# EFM32PG1B100F128GM32 register map
File version: 4.2.0
Registers are 32-bit, read-write, reset 0x0 unless marked. A register's access mark holds for its fields unless they carry their own. Offsets are from the block's base; [hi:lo] are bit positions; 'fields as' and 'values as' point back to an identical list.

## EMU
Base 0x400E3000
0x00 CTRL — Control Register
  [1] EM2BLOCK — Energy Mode 2 Block
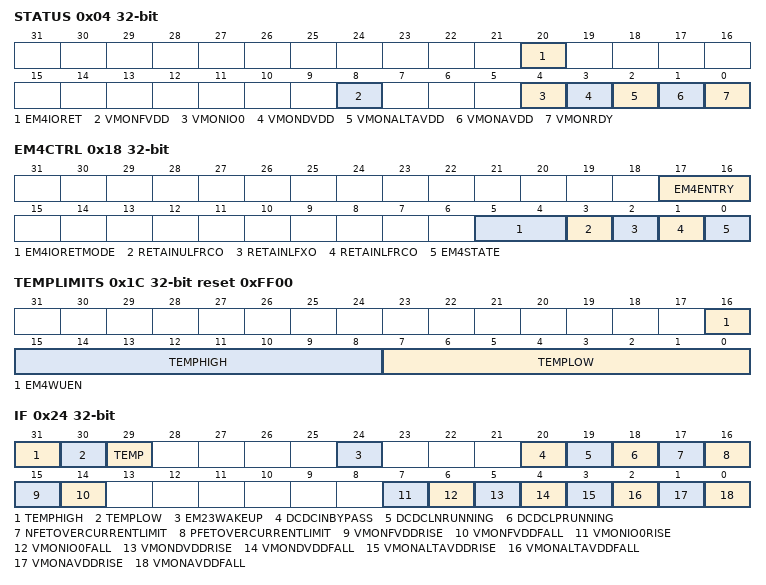
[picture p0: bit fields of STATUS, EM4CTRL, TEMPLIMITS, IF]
0x04 STATUS ro
  [20] EM4IORET — IO Retention Status
  [8] VMONFVDD — VMON VDDFLASH Channel.
  [4] VMONIO0 — VMON IOVDD0 Channel.
  [3] VMONDVDD — VMON DVDD Channel.
  [2] VMONALTAVDD — Alternate VMON AVDD Channel.
  [1] VMONAVDD — VMON AVDD Channel.
  [0] VMONRDY — VMON ready
0x08 LOCK — Configuration Lock Register
  [15:0] LOCKKEY — Configuration Lock Key
    0=UNLOCKED; 1=LOCKED
0x0C RAM0CTRL — Memory Control Register
  [3:0] RAMPOWERDOWN — RAM0 blockset power-down
    0=NONE (None of the RAM blocks powered down); 8=BLK4 (Power down RAM blocks 4 and above (address range 0x20006000-0x20007BFF)); 12=BLK3TO4 (Power down RAM blocks 3 and above (address range 0x20004000-0x20007BFF)); 14=BLK2TO4 (Power down RAM blocks 2 and above (address range 0x20002000-0x20007BFF)); 15=BLK1TO4 (Power down RAM blocks 1 and above (address range 0x20001000-0x20007BFF))
0x10 CMD wo — Command Register
  [0] EM4UNLATCH
0x14 PERACTCONF — Peripheral to Peripheral Activation Clock Configuration
  [0] RACPER — Enable PER clock when RAC is activated
0x18 EM4CTRL — EM4 Control Register
  [17:16] EM4ENTRY wo — Energy Mode 4 Entry
  [5:4] EM4IORETMODE — EM4 IO Retention Disable
    0=DISABLE (No Retention: Pads enter reset state when entering EM4); 1=EM4EXIT (Retention through EM4: Pads enter reset state when exiting EM4); 2=SWUNLATCH (Retention through EM4 and Wakeup: software writes UNLATCH register to remove retention)
  [3] RETAINULFRCO — ULFRCO Retain during EM4S
  [2] RETAINLFXO — LFXO Retain during EM4
  [1] RETAINLFRCO — LFRCO Retain during EM4
  [0] EM4STATE — Energy Mode 4 State
0x1C TEMPLIMITS reset 0xFF00 — Temperature limits for interrupt generation
  [16] EM4WUEN — Enable EM4 Wakeup due to low/high temerature
  [15:8] TEMPHIGH — Temperature High Limit
  [7:0] TEMPLOW — Temperature Low Limit
0x20 TEMP ro — Value of last temperature measurement
  [7:0] TEMP — Temperature Measurement
0x24 IF ro — Interrupt Flag Register
  [31] TEMPHIGH — Temperature High Limit Reached
  [30] TEMPLOW — Temperature Low Limit Reached
  [29] TEMP — New Temperature Measurement Valid
  [24] EM23WAKEUP — Wakeup IRQ from EM2 and EM3
  [20] DCDCINBYPASS — DCDC is in bypass
  [19] DCDCLNRUNNING — LN mode is running
  [18] DCDCLPRUNNING — LP mode is running
  [17] NFETOVERCURRENTLIMIT — NFET current limit hit
  [16] PFETOVERCURRENTLIMIT — PFET current limit hit
  [15] VMONFVDDRISE — VMON VDDFLASH Channel Rise
  [14] VMONFVDDFALL — VMON VDDFLASH Channel Fall
  [7] VMONIO0RISE — VMON IOVDD0 Channel Rise
  [6] VMONIO0FALL — VMON IOVDD0 Channel Fall
  [5] VMONDVDDRISE — VMON DVDD Channel Rise
  [4] VMONDVDDFALL — VMON DVDD Channel Fall
  [3] VMONALTAVDDRISE — Alternate VMON AVDD Channel Rise
  [2] VMONALTAVDDFALL — Alternate VMON AVDD Channel Fall
  [1] VMONAVDDRISE — VMON AVDD Channel Rise
  [0] VMONAVDDFALL — VMON AVDD Channel Fall
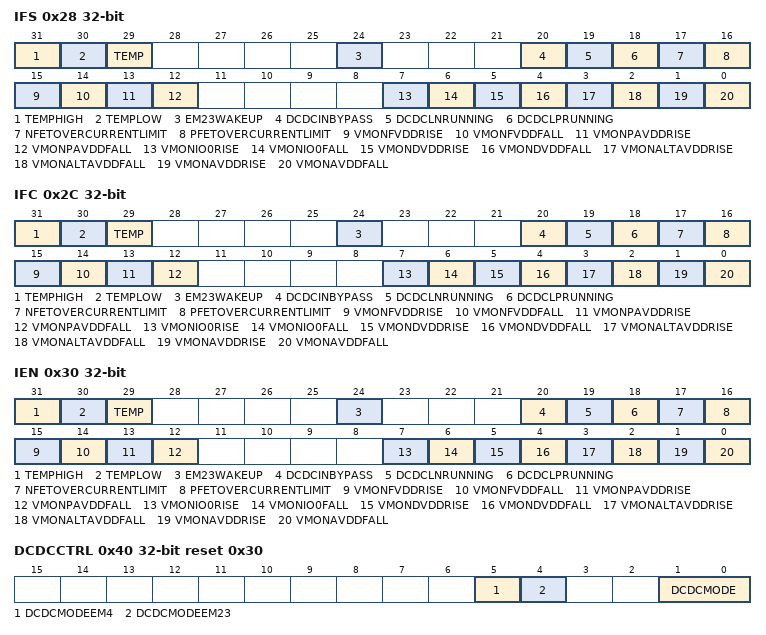
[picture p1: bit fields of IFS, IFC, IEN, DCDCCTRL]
0x28 IFS wo — Interrupt Flag Set Register
  [31] TEMPHIGH — Set TEMPHIGH Interrupt Flag
  [30] TEMPLOW — Set TEMPLOW Interrupt Flag
  [29] TEMP — Set TEMP Interrupt Flag
  [24] EM23WAKEUP — Set EM23WAKEUP Interrupt Flag
  [20] DCDCINBYPASS — Set DCDCINBYPASS Interrupt Flag
  [19] DCDCLNRUNNING — Set DCDCLNRUNNING Interrupt Flag
  [18] DCDCLPRUNNING — Set DCDCLPRUNNING Interrupt Flag
  [17] NFETOVERCURRENTLIMIT — Set NFETOVERCURRENTLIMIT Interrupt Flag
  [16] PFETOVERCURRENTLIMIT — Set PFETOVERCURRENTLIMIT Interrupt Flag
  [15] VMONFVDDRISE — Set VMONFVDDRISE Interrupt Flag
  [14] VMONFVDDFALL — Set VMONFVDDFALL Interrupt Flag
  [13] VMONPAVDDRISE — Set VMONPAVDDRISE Interrupt Flag
  [12] VMONPAVDDFALL — Set VMONPAVDDFALL Interrupt Flag
  [7] VMONIO0RISE — Set VMONIO0RISE Interrupt Flag
  [6] VMONIO0FALL — Set VMONIO0FALL Interrupt Flag
  [5] VMONDVDDRISE — Set VMONDVDDRISE Interrupt Flag
  [4] VMONDVDDFALL — Set VMONDVDDFALL Interrupt Flag
  [3] VMONALTAVDDRISE — Set VMONALTAVDDRISE Interrupt Flag
  [2] VMONALTAVDDFALL — Set VMONALTAVDDFALL Interrupt Flag
  [1] VMONAVDDRISE — Set VMONAVDDRISE Interrupt Flag
  [0] VMONAVDDFALL — Set VMONAVDDFALL Interrupt Flag
0x2C IFC wo — Interrupt Flag Clear Register
  [31] TEMPHIGH — Clear TEMPHIGH Interrupt Flag
  [30] TEMPLOW — Clear TEMPLOW Interrupt Flag
  [29] TEMP — Clear TEMP Interrupt Flag
  [24] EM23WAKEUP — Clear EM23WAKEUP Interrupt Flag
  [20] DCDCINBYPASS — Clear DCDCINBYPASS Interrupt Flag
  [19] DCDCLNRUNNING — Clear DCDCLNRUNNING Interrupt Flag
  [18] DCDCLPRUNNING — Clear DCDCLPRUNNING Interrupt Flag
  [17] NFETOVERCURRENTLIMIT — Clear NFETOVERCURRENTLIMIT Interrupt Flag
  [16] PFETOVERCURRENTLIMIT — Clear PFETOVERCURRENTLIMIT Interrupt Flag
  [15] VMONFVDDRISE — Clear VMONFVDDRISE Interrupt Flag
  [14] VMONFVDDFALL — Clear VMONFVDDFALL Interrupt Flag
  [13] VMONPAVDDRISE — Clear VMONPAVDDRISE Interrupt Flag
  [12] VMONPAVDDFALL — Clear VMONPAVDDFALL Interrupt Flag
  [7] VMONIO0RISE — Clear VMONIO0RISE Interrupt Flag
  [6] VMONIO0FALL — Clear VMONIO0FALL Interrupt Flag
  [5] VMONDVDDRISE — Clear VMONDVDDRISE Interrupt Flag
  [4] VMONDVDDFALL — Clear VMONDVDDFALL Interrupt Flag
  [3] VMONALTAVDDRISE — Clear VMONALTAVDDRISE Interrupt Flag
  [2] VMONALTAVDDFALL — Clear VMONALTAVDDFALL Interrupt Flag
  [1] VMONAVDDRISE — Clear VMONAVDDRISE Interrupt Flag
  [0] VMONAVDDFALL — Clear VMONAVDDFALL Interrupt Flag
0x30 IEN — Interrupt Enable Register
  [31] TEMPHIGH — TEMPHIGH Interrupt Enable
  [30] TEMPLOW — TEMPLOW Interrupt Enable
  [29] TEMP — TEMP Interrupt Enable
  [24] EM23WAKEUP — EM23WAKEUP Interrupt Enable
  [20] DCDCINBYPASS — DCDCINBYPASS Interrupt Enable
  [19] DCDCLNRUNNING — DCDCLNRUNNING Interrupt Enable
  [18] DCDCLPRUNNING — DCDCLPRUNNING Interrupt Enable
  [17] NFETOVERCURRENTLIMIT — NFETOVERCURRENTLIMIT Interrupt Enable
  [16] PFETOVERCURRENTLIMIT — PFETOVERCURRENTLIMIT Interrupt Enable
  [15] VMONFVDDRISE — VMONFVDDRISE Interrupt Enable
  [14] VMONFVDDFALL — VMONFVDDFALL Interrupt Enable
  [13] VMONPAVDDRISE — VMONPAVDDRISE Interrupt Enable
  [12] VMONPAVDDFALL — VMONPAVDDFALL Interrupt Enable
  [7] VMONIO0RISE — VMONIO0RISE Interrupt Enable
  [6] VMONIO0FALL — VMONIO0FALL Interrupt Enable
  [5] VMONDVDDRISE — VMONDVDDRISE Interrupt Enable
  [4] VMONDVDDFALL — VMONDVDDFALL Interrupt Enable
  [3] VMONALTAVDDRISE — VMONALTAVDDRISE Interrupt Enable
  [2] VMONALTAVDDFALL — VMONALTAVDDFALL Interrupt Enable
  [1] VMONAVDDRISE — VMONAVDDRISE Interrupt Enable
  [0] VMONAVDDFALL — VMONAVDDFALL Interrupt Enable
0x34 PWRLOCK — Regulator and Supply Lock Register
  [15:0] LOCKKEY — Regulator and Supply Configuration Lock Key
    0=UNLOCKED; 1=LOCKED
0x38 PWRCFG — Power Configuration Register.
  [3:0] PWRCFG — Power Configuration
    0=STARTUP (Power up configuration. Works with any external configuration.); 1=NODCDC (DCDC Disabled. AVDD Bypassed to DVDD internally); 2=DCDCTODVDD (DCDC filterred and routed to DVDD)
0x3C PWRCTRL — Power Control Register.
  [5] ANASW — Analog Switch Selection
0x40 DCDCCTRL reset 0x30 — DCDC Control
  [5] DCDCMODEEM4 — Reserved for internal use. Do not change.
  [4] DCDCMODEEM23 — Reserved for internal use. Do not change.
  [1:0] DCDCMODE — Regulator Mode
    0=BYPASS (DCDC regulator is operating in bypass mode.); 1=LOWNOISE (DCDC regulator is operating in low noise mode.); 2=LOWPOWER (DCDC regulator is operating in low power mode.); 3=OFF (DCDC regulator is off. Note: DVDD must be supplied externally)
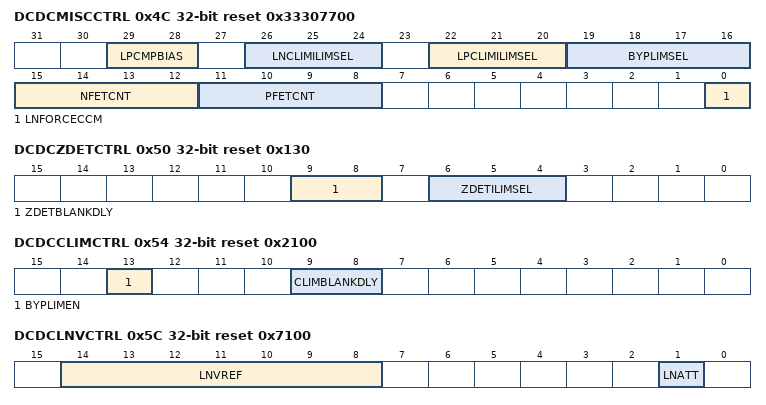
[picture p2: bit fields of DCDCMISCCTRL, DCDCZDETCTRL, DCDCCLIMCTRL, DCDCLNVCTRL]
0x4C DCDCMISCCTRL reset 0x33307700 — DCDC Miscellaneous Control Register
  [29:28] LPCMPBIAS — LP mode comparator bias selection
    0=BIAS0 (Nominal load current less than 10uA.); 1=BIAS1 (Nominal load current less than 100uA.); 2=BIAS2 (Nominal load current less than 1mA.); 3=BIAS3 (Nominal load current less than 10mA.)
  [26:24] LNCLIMILIMSEL — Current limiter current threshold selection during low noise mode
  [22:20] LPCLIMILIMSEL — Current limiter current threshold selection during low power mode
  [19:16] BYPLIMSEL — Current Limit In Bypass Mode
  [15:12] NFETCNT — NFET switch number selection
  [11:8] PFETCNT — PFET switch number selection
  [0] LNFORCECCM — Force DCDC into CCM mode in low noise operation
0x50 DCDCZDETCTRL reset 0x130 — DCDC Power Train NFET Zero Current Detector Control Register
  [9:8] ZDETBLANKDLY — Reserved for internal use. Do not change.
  [6:4] ZDETILIMSEL — Reverse current limit level for zero detector
0x54 DCDCCLIMCTRL reset 0x2100 — DCDC Power Train PFET Current Limiter Control Register
  [13] BYPLIMEN — Bypass Current Limit Enable
  [9:8] CLIMBLANKDLY — Reserved for internal use. Do not change.
0x5C DCDCLNVCTRL reset 0x7100 — DCDC Low Noise Voltage Register
  [14:8] LNVREF — Low Noise Mode VREF Trim
  [1] LNATT — Low Noise Mode Feedback Attenuation
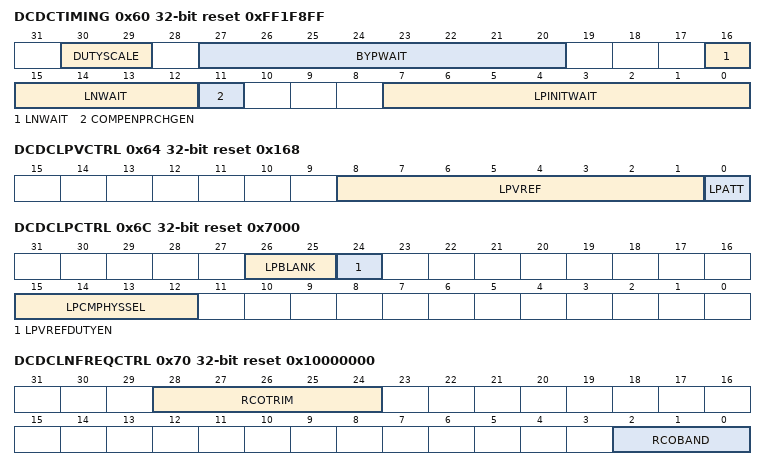
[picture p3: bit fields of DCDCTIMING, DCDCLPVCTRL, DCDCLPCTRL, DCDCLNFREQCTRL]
0x60 DCDCTIMING reset 0xFF1F8FF — DCDC Controller Timing Value Register
  [30:29] DUTYSCALE — Select bias duty cycle clock.
  [27:20] BYPWAIT — Bypass mode transition from low power or low noise modes wait
  [16:12] LNWAIT — Low Noise Controller Initialization wait time
  [11] COMPENPRCHGEN — LN mode precharge enable
  [7:0] LPINITWAIT — Low power initialization wait time
0x64 DCDCLPVCTRL reset 0x168 — DCDC Low Power Voltage Register
  [8:1] LPVREF — LP mode vref trim
  [0] LPATT — Low power feedback attenuation
0x6C DCDCLPCTRL reset 0x7000 — DCDC Low Power Control Register
  [26:25] LPBLANK — Reserved for internal use. Do not change.
  [24] LPVREFDUTYEN — Lp mode duty cycling enable
  [15:12] LPCMPHYSSEL — LP mode hysteresis selection
0x70 DCDCLNFREQCTRL reset 0x10000000 — DCDC Low Noise Controller Frequency Control
  [28:24] RCOTRIM — Reserved for internal use. Do not change.
  [2:0] RCOBAND — LN mode RCO frequency band selection
0x78 DCDCSYNC ro — DCDC Read Status Register
  [0] DCDCCTRLBUSY — DCDC CTRL Register Transfer Busy.
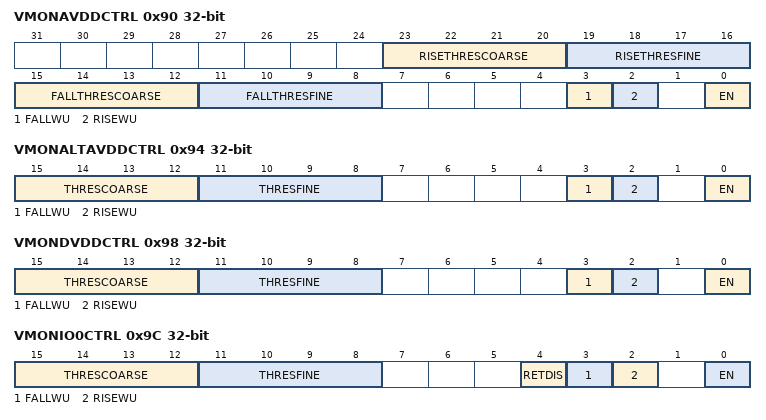
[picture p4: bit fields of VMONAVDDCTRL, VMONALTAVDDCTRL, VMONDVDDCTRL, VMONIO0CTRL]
0x90 VMONAVDDCTRL — VMON AVDD Channel Control
  [23:20] RISETHRESCOARSE — Rising Threshold Coarse Adjust
  [19:16] RISETHRESFINE — Rising Threshold Fine Adjust
  [15:12] FALLTHRESCOARSE — Falling Threshold Coarse Adjust
  [11:8] FALLTHRESFINE — Falling Threshold Fine Adjust
  [3] FALLWU — Fall Wakeup
  [2] RISEWU — Rise Wakeup
  [0] EN — Enable
0x94 VMONALTAVDDCTRL — Alternate VMON AVDD Channel Control
  [15:12] THRESCOARSE — Threshold Coarse Adjust
  [11:8] THRESFINE — Threshold Fine Adjust
  [3] FALLWU — Fall Wakeup
  [2] RISEWU — Rise Wakeup
  [0] EN — Enable
0x98 VMONDVDDCTRL — VMON DVDD Channel Control
  fields as VMONALTAVDDCTRL
0x9C VMONIO0CTRL — VMON IOVDD0 Channel Control
  [15:12] THRESCOARSE — Threshold Coarse Adjust
  [11:8] THRESFINE — Threshold Fine Adjust
  [4] RETDIS — EM4 IO0 Retention disable
  [3] FALLWU — Fall Wakeup
  [2] RISEWU — Rise Wakeup
  [0] EN — Enable
